# STM32U073 register map
File version: 1.0
CPU: CM0+ r0p1, little endian, MPU, no FPU, 4 interrupt priority bits
Registers are 32-bit, read-write, reset 0x0 unless marked. A register's access mark holds for its fields unless they carry their own. Offsets are from the block's base; [hi:lo] are bit positions.

## IWDG — IWDG address block description
Base 0x40003000
0x00 KR 16-bit wo — IWDG key register
  [15:0] KEY — Key value (write only, read 0x0000) These bits can be used for several functions, depending upon the value written by the application: - 0xAAAA: reloads the RL[11:0] value into the IWDCNT down-counter (watchdog refresh), and write-protects registers. This value must be written by software at regular intervals, otherwise the watchdog generates a reset when the counter reaches 0. - 0x5555: enables write-accesses to the registers. - 0xCCCC: enables the watchdog (except if the hardware watchdog option is selected) and write-protects registers. - values different from 0x5555: write-protects registers. Note that only IWDG_PR, IWDG_RLR, IWDG_EWCR and IWDG_WINR registers have a write-protection mechanism.
    0x5555=Unlock (Enable access to PR, RLR and WINR registers); 0xAAAA=Feed watchdog with RLR register value; 0xCCCC=Start the watchdog
0x04 PR 16-bit — IWDG prescaler register
  [3:0] PR — Prescaler divider These bits are write access protected, see Section126.4.6. They are written by software to select the prescaler divider feeding the counter clock. PVU bit of the IWDG status register (IWDG_SR) must be reset to be able to change the prescaler divider. Others: divider / 1024 Note: Reading this register returns the prescaler value from the V<sub>DD</sub> voltage domain. This value may not be up to date/valid if a write operation to this register is ongoing. For this reason the value read from this register is valid only when the PVU bit in the IWDG status register (IWDG_SR) is reset.
    0=DivideBy4 (Divider /4); 1=DivideBy8 (Divider /8); 2=DivideBy16 (Divider /16); 3=DivideBy32 (Divider /32); 4=DivideBy64 (Divider /64); 5=DivideBy128 (Divider /128); 6=DivideBy256 (Divider /256); 7=DivideBy512 (Divider /512); other=DivideBy1024 (Divider /1024)
0x08 RLR 16-bit reset 0xFFF — IWDG reload register
  [11:0] RL — Watchdog counter reload value These bits are write access protected, see Section126.4.6. They are written by software to define the value to be loaded in the watchdog counter each time the value 0xAAAA is written in the IWDG key register (IWDG_KR). The watchdog counter counts down from this value. The timeout period is a function of this value and the prescaler.clock. It is not recommended to set RL[11:0] to a value lower than 2. The RVU bit in the IWDG status register (IWDG_SR) must be reset to be able to change the reload value. Note: Reading this register returns the reload value from the V<sub>DD</sub> voltage domain. This value may not be up to date/valid if a write operation to this register is ongoing, hence the value read from this register is valid only when the RVU bit in the IWDG status register (IWDG_SR) is reset.
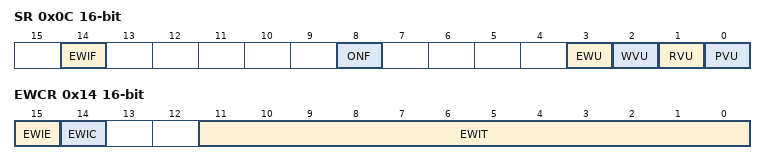
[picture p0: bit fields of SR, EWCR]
0x0C SR 16-bit ro — IWDG status register
  [14] EWIF — Watchdog early interrupt flag This bit is set to 1 by hardware in order to indicate that an early interrupt is pending. This bit must be cleared by the software by writing the bit EWIC of IWDG_EWCR register to 1.
    0=NotPending (No pending interrupt); 1=Pending (Interrupt pending)
  [8] ONF — Watchdog enable status bit Set to 1 by hardware as soon as the IWDG is started. In software mode, it remains to '1' until the IWDG is reset. In hardware mode, this bit is always set to '1'.
    0=NotActivated (IWDG is not activated); 1=Activated (IWDG is activated)
  [3] EWU — Watchdog interrupt comparator value update This bit is set by hardware to indicate that an update of the interrupt comparator value (EWIT[11:0]) or an update of the EWIE is ongoing. It is reset by hardware when the update operation is completed in the V<sub>DD</sub> voltage domain (takes up to one period of presc_ck and two periods of the IWDG kernel clock iwdg_ker_ck). The EWIT[11:0] and EWIE fields can be updated only when EWU bit is reset.
    0=Idle (No update on-going); 1=Busy (Update on-going)
  [2] WVU — Watchdog counter window value update This bit is set by hardware to indicate that an update of the window value is ongoing. It is reset by hardware when the reload value update operation is completed in the V<sub>DD</sub> voltage domain (takes up to one period of presc_ck and two periods of the IWDG kernel clock iwdg_ker_ck). The window value can be updated only when WVU bit is reset. This bit is generated only if generic window = 1.
    0=Idle (No update on-going); 1=Busy (Update on-going)
  [1] RVU — Watchdog counter reload value update This bit is set by hardware to indicate that an update of the reload value is ongoing. It is reset by hardware when the reload value update operation is completed in the V<sub>DD</sub> voltage domain (takes up to six periods of the IWDG kernel clock iwdg_ker_ck). The reload value can be updated only when RVU bit is reset.
    0=Idle (No update on-going); 1=Busy (Update on-going)
  [0] PVU — Watchdog prescaler value update This bit is set by hardware to indicate that an update of the prescaler value is ongoing. It is reset by hardware when the prescaler update operation is completed in the V<sub>DD</sub> voltage domain (takes up to six periods of the IWDG kernel clock iwdg_ker_ck). The prescaler value can be updated only when PVU bit is reset.
    0=Idle (No update on-going); 1=Busy (Update on-going)
0x10 WINR 16-bit reset 0xFFF — IWDG window register
  [11:0] WIN — Watchdog counter window value These bits are write access protected, see Section126.4.6.They contain the high limit of the window value to be compared with the downcounter. To prevent a reset, the IWDCNT downcounter must be reloaded when its value is lower than WIN[11:0]1+11 and greater than 1. The WVU bit in the IWDG status register (IWDG_SR) must be reset to be able to change the reload value. Note: Reading this register returns the reload value from the V<sub>DD</sub> voltage domain. This value may not be valid if a write operation to this register is ongoing. For this reason the value read from this register is valid only when the WVU bit in the IWDG status register (IWDG_SR) is reset.
0x14 EWCR 16-bit access per field — IWDG early wake-up interrupt register
  [15] EWIE rw — Watchdog early interrupt enable Set and reset by software. The EWU bit in the IWDG status register (IWDG_SR) must be reset to be able to change the value of this bit.
  [14] EWIC wo — Watchdog early interrupt acknowledge The software must write a 1 into this bit in order to acknowledge the early wake-up interrupt and to clear the EWIF flag. Writing 0 has not effect, reading this flag returns a 0.
  [11:0] EWIT rw — Watchdog counter window value These bits are write access protected (see Section126.4.6). They are written by software to define at which position of the IWDCNT down-counter the early wake-up interrupt must be generated. The early interrupt is generated when the IWDCNT is lower or equal to EWIT[11:0]1-11. EWIT[11:0] must be bigger than 1. An interrupt is generated only if EWIE = 1. The EWU bit in the IWDG status register (IWDG_SR) must be reset to be able to change the reload value. Note: Reading this register returns the Early wake-up comparator value and the Interrupt enable bit from the V<sub>DD</sub> voltage domain. This value may not be up to date/valid if a write operation to this register is ongoing, hence the value read from this register is valid only when the EWU bit in the IWDG status register (IWDG_SR) is reset.
